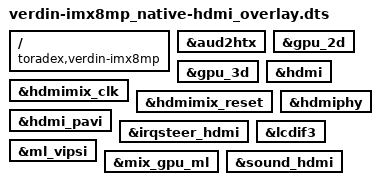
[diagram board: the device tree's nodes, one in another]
// SPDX-License-Identifier: GPL-2.0-or-later OR MIT
/*
 * Copyright 2021 Toradex
 */

// Verdin native HDMI interface.

/dts-v1/;
/plugin/;

/ {
	compatible = "toradex,verdin-imx8mp";
};

&aud2htx {
	status = "okay";
};

&gpu_2d {
	status = "okay";
};

&gpu_3d {
	status = "okay";
};

&hdmi {
	status = "okay";
};

&hdmimix_clk {
	status = "okay";
};

&hdmimix_reset {
	status = "okay";
};

&hdmiphy {
	status = "okay";
};

&hdmi_pavi {
	status = "okay";
};

&irqsteer_hdmi {
	status = "okay";
};

/* LCDIF to on-SoC Samsung HDMI PHY */
&lcdif3 {
	status = "okay";
};

&ml_vipsi {
	status = "okay";
};

&mix_gpu_ml {
	status = "okay";
};

&sound_hdmi {
	status = "okay";
};

